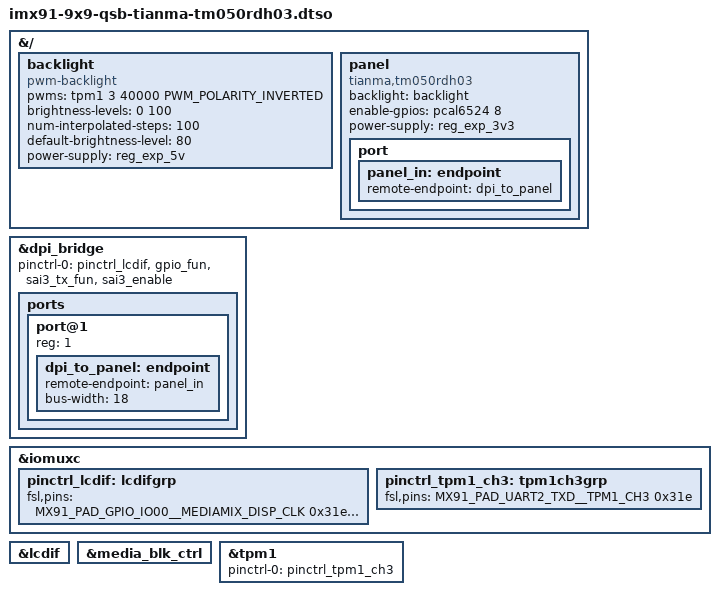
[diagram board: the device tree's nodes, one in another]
// SPDX-License-Identifier: (GPL-2.0+ OR MIT)
/*
 * Copyright 2026 NXP
 */

/dts-v1/;
/plugin/;

#include <dt-bindings/gpio/gpio.h>
#include <dt-bindings/pwm/pwm.h>
#include "imx91-pinfunc.h"

&{/} {
	backlight: backlight {
		compatible = "pwm-backlight";
		pwms = <&tpm1 3 40000 PWM_POLARITY_INVERTED>;	/* 25KHz PWM */
		brightness-levels = <0 100>;
		num-interpolated-steps = <100>;
		default-brightness-level = <80>;
		power-supply = <&reg_exp_5v>;
	};

	panel {
		compatible = "tianma,tm050rdh03";
		backlight = <&backlight>;
		enable-gpios = <&pcal6524 8 GPIO_ACTIVE_HIGH>;
		power-supply = <&reg_exp_3v3>;

		port {
			panel_in: endpoint {
				remote-endpoint = <&dpi_to_panel>;
			};
		};
	};
};

&dpi_bridge {
	pinctrl-names = "default";
	pinctrl-0 = <&pinctrl_lcdif>, <&gpio_fun>, <&sai3_tx_fun>, <&sai3_enable>;
	status = "okay";

	ports {
		#address-cells = <1>;
		#size-cells = <0>;

		port@1 {
			reg = <1>;

			dpi_to_panel: endpoint {
				remote-endpoint = <&panel_in>;
				bus-width = <18>;
			};
		};
	};
};

&iomuxc {
	pinctrl_lcdif: lcdifgrp {
		fsl,pins = <
			MX91_PAD_GPIO_IO00__MEDIAMIX_DISP_CLK		0x31e
			MX91_PAD_GPIO_IO01__MEDIAMIX_DISP_DE		0x31e
			MX91_PAD_GPIO_IO02__MEDIAMIX_DISP_VSYNC		0x31e
			MX91_PAD_GPIO_IO03__MEDIAMIX_DISP_HSYNC		0x31e
			MX91_PAD_GPIO_IO04__MEDIAMIX_DISP_DATA0		0x31e
			MX91_PAD_GPIO_IO05__MEDIAMIX_DISP_DATA1		0x31e
			MX91_PAD_GPIO_IO06__MEDIAMIX_DISP_DATA2		0x31e
			MX91_PAD_GPIO_IO07__MEDIAMIX_DISP_DATA3		0x31e
			MX91_PAD_GPIO_IO08__MEDIAMIX_DISP_DATA4		0x31e
			MX91_PAD_GPIO_IO09__MEDIAMIX_DISP_DATA5		0x31e
			MX91_PAD_GPIO_IO10__MEDIAMIX_DISP_DATA6		0x31e
			MX91_PAD_GPIO_IO11__MEDIAMIX_DISP_DATA7		0x31e
			MX91_PAD_GPIO_IO12__MEDIAMIX_DISP_DATA8		0x31e
			MX91_PAD_GPIO_IO13__MEDIAMIX_DISP_DATA9		0x31e
			MX91_PAD_GPIO_IO14__MEDIAMIX_DISP_DATA10	0x31e
			MX91_PAD_GPIO_IO15__MEDIAMIX_DISP_DATA11	0x31e
			MX91_PAD_GPIO_IO16__MEDIAMIX_DISP_DATA12	0x31e
			MX91_PAD_GPIO_IO17__MEDIAMIX_DISP_DATA13	0x31e
			MX91_PAD_GPIO_IO18__MEDIAMIX_DISP_DATA14	0x31e
			MX91_PAD_GPIO_IO19__MEDIAMIX_DISP_DATA15	0x31e
			MX91_PAD_GPIO_IO20__MEDIAMIX_DISP_DATA16	0x31e
			MX91_PAD_GPIO_IO21__MEDIAMIX_DISP_DATA17	0x31e
		>;
	};

	pinctrl_tpm1_ch3: tpm1ch3grp {
		fsl,pins = <
			MX91_PAD_UART2_TXD__TPM1_CH3			0x31e
		>;
	};
};

&lcdif {
	status = "okay";
};

&media_blk_ctrl {
	status = "okay";
};

&tpm1 {
	pinctrl-names = "default";
	pinctrl-0 = <&pinctrl_tpm1_ch3>;
	status = "okay";
};
